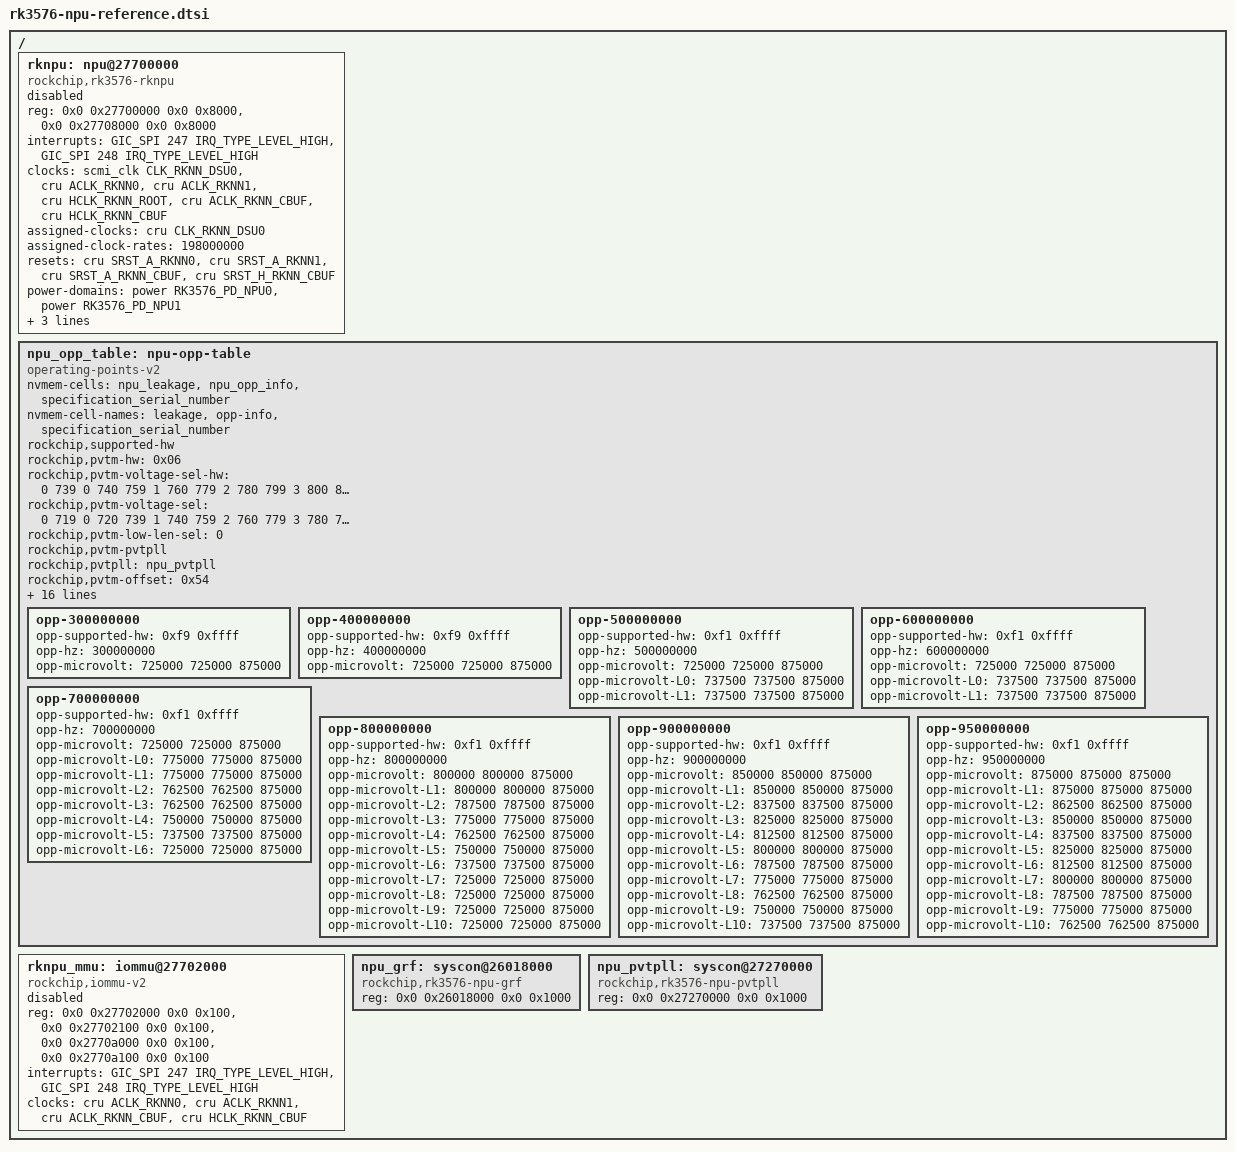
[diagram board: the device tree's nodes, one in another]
// SPDX-License-Identifier: (GPL-2.0+ OR MIT)
/*
 * Copyright (c) 2024 Rockchip Electronics Co., Ltd.
 * 
 * NPU Node Reference - RK3576
 * 
 * Usage:
 *   #include "rk3576-npu-reference.dtsi"
 *   
 * Board-specific configuration (optional):
 *   - Enable desired NPU power domains
 *   - Adjust OPP frequencies
 *   - Configure GPIO reset pins
 *   - Add board-specific iommu mappings
 */

/ {
    // NPU控制器 - 核心节点
    rknpu: npu@27700000 {
        compatible = "rockchip,rk3576-rknpu";
        reg = <0x0 0x27700000 0x0 0x8000>,
              <0x0 0x27708000 0x0 0x8000>;
        interrupts = <GIC_SPI 247 IRQ_TYPE_LEVEL_HIGH>,
                     <GIC_SPI 248 IRQ_TYPE_LEVEL_HIGH>;
        interrupt-names = "npu0_irq", "npu1_irq";
        
        // 时钟配置
        clocks = <&scmi_clk CLK_RKNN_DSU0>, <&cru ACLK_RKNN0>, <&cru ACLK_RKNN1>, 
                 <&cru HCLK_RKNN_ROOT>, <&cru ACLK_RKNN_CBUF>, <&cru HCLK_RKNN_CBUF>;
        clock-names = "clk_npu", "aclk0", "aclk1", "hclk_root",
                      "aclk_cbuf", "hclk_cbuf";
        
        // 时钟分频设置
        assigned-clocks = <&cru CLK_RKNN_DSU0>;
        assigned-clock-rates = <198000000>;
        
        // 复位控制
        resets = <&cru SRST_A_RKNN0>, <&cru SRST_A_RKNN1>,
                 <&cru SRST_A_RKNN_CBUF>, <&cru SRST_H_RKNN_CBUF>;
        reset-names = "srst_a0", "srst_a1",
                      "srst_a_cbuf", "srst_h_cbuf";
        
        // 电源域
        power-domains = <&power RK3576_PD_NPU0>, <&power RK3576_PD_NPU1>;
        power-domain-names = "npu0", "npu1";
        
        // 性能表 - 从npu_opp_table引用
        operating-points-v2 = <&npu_opp_table>;
        
        // IOMMU - 用于DMA地址转换
        iommus = <&rknpu_mmu>;
        
        // 热管理
        #cooling-cells = <2>;
        dynamic-power-coefficient = <2570>;
        
        // 默认禁用，板级dts覆盖为"okay"
        status = "disabled";
    };

    // NPU电源管理表 - 包含电压/频率调优
    npu_opp_table: npu-opp-table {
        compatible = "operating-points-v2";
        
        // OTC OTP数据引用
        nvmem-cells = <&npu_leakage>, <&npu_opp_info>, <&specification_serial_number>;
        nvmem-cell-names = "leakage", "opp-info", "specification_serial_number";
        
        // 硬件版本支持
        rockchip,supported-hw;
        
        // PVTM (Process, Voltage, Temperature Monitoring) 配置
        rockchip,pvtm-hw = <0x06>;
        rockchip,pvtm-voltage-sel-hw = <
            0   739   0
            740 759   1
            760 779   2
            780 799   3
            800 819   4
            820 839   5
            840 859   6
            860 879   7
            880 899   8
            900 9999  9
        >;
        rockchip,pvtm-voltage-sel = <
            0   719   0
            720 739   1
            740 759   2
            760 779   3
            780 799   4
            800 819   5
            820 839   6
            840 859   7
            860 879   8
            880 899   9
            900 9999  10
        >;
        rockchip,pvtm-low-len-sel = <0>;
        rockchip,pvtm-pvtpll;
        rockchip,pvtpll = <&npu_pvtpll>;
        rockchip,pvtm-offset = <0x54>;
        rockchip,pvtm-sample-time = <1100>;
        rockchip,pvtm-freq = <800000>;
        rockchip,pvtm-volt = <750000>;
        rockchip,pvtm-ref-temp = <35>;
        rockchip,pvtm-temp-prop = <0 0>;
        rockchip,pvtm-thermal-zone = "npu-thermal";
        
        // GRF寄存器访问
        rockchip,grf = <&npu_grf>;
        
        // 内存读取 Margin 调优
        volt-mem-read-margin = <
            855000  1
            765000  2
            675000  3
            495000  4
        >;
        
        // 频率交叉点
        intermediate-threshold-freq = <300000>;
        
        // OPP依赖的时钟
        rockchip,opp-clocks = <&cru ACLK_RKNN_CBUF>,
                              <&cru HCLK_RKNN_CBUF>,
                              <&cru PCLK_NPUTOP_ROOT>;
        
        // 温度迟滞和低频电压
        rockchip,temp-hysteresis = <5000>;
        rockchip,low-temp = <15000>;
        rockchip,low-temp-min-volt = <750000>;
        rockchip,init-freq = <950000>;
        
        // 典型 OPP 表 ( RK3576标准版 )
        opp-300000000 {
            opp-supported-hw = <0xf9 0xffff>;
            opp-hz = /bits/ 64 <300000000>;
            opp-microvolt = <725000 725000 875000>;
        };
        opp-400000000 {
            opp-supported-hw = <0xf9 0xffff>;
            opp-hz = /bits/ 64 <400000000>;
            opp-microvolt = <725000 725000 875000>;
        };
        opp-500000000 {
            opp-supported-hw = <0xf1 0xffff>;
            opp-hz = /bits/ 64 <500000000>;
            opp-microvolt = <725000 725000 875000>;
            opp-microvolt-L0 = <737500 737500 875000>;
            opp-microvolt-L1 = <737500 737500 875000>;
        };
        opp-600000000 {
            opp-supported-hw = <0xf1 0xffff>;
            opp-hz = /bits/ 64 <600000000>;
            opp-microvolt = <725000 725000 875000>;
            opp-microvolt-L0 = <737500 737500 875000>;
            opp-microvolt-L1 = <737500 737500 875000>;
        };
        opp-700000000 {
            opp-supported-hw = <0xf1 0xffff>;
            opp-hz = /bits/ 64 <700000000>;
            opp-microvolt = <725000 725000 875000>;
            opp-microvolt-L0 = <775000 775000 875000>;
            opp-microvolt-L1 = <775000 775000 875000>;
            opp-microvolt-L2 = <762500 762500 875000>;
            opp-microvolt-L3 = <762500 762500 875000>;
            opp-microvolt-L4 = <750000 750000 875000>;
            opp-microvolt-L5 = <737500 737500 875000>;
            opp-microvolt-L6 = <725000 725000 875000>;
        };
        opp-800000000 {
            opp-supported-hw = <0xf1 0xffff>;
            opp-hz = /bits/ 64 <800000000>;
            opp-microvolt = <800000 800000 875000>;
            opp-microvolt-L1 = <800000 800000 875000>;
            opp-microvolt-L2 = <787500 787500 875000>;
            opp-microvolt-L3 = <775000 775000 875000>;
            opp-microvolt-L4 = <762500 762500 875000>;
            opp-microvolt-L5 = <750000 750000 875000>;
            opp-microvolt-L6 = <737500 737500 875000>;
            opp-microvolt-L7 = <725000 725000 875000>;
            opp-microvolt-L8 = <725000 725000 875000>;
            opp-microvolt-L9 = <725000 725000 875000>;
            opp-microvolt-L10 = <725000 725000 875000>;
        };
        opp-900000000 {
            opp-supported-hw = <0xf1 0xffff>;
            opp-hz = /bits/ 64 <900000000>;
            opp-microvolt = <850000 850000 875000>;
            opp-microvolt-L1 = <850000 850000 875000>;
            opp-microvolt-L2 = <837500 837500 875000>;
            opp-microvolt-L3 = <825000 825000 875000>;
            opp-microvolt-L4 = <812500 812500 875000>;
            opp-microvolt-L5 = <800000 800000 875000>;
            opp-microvolt-L6 = <787500 787500 875000>;
            opp-microvolt-L7 = <775000 775000 875000>;
            opp-microvolt-L8 = <762500 762500 875000>;
            opp-microvolt-L9 = <750000 750000 875000>;
            opp-microvolt-L10 = <737500 737500 875000>;
        };
        opp-950000000 {
            opp-supported-hw = <0xf1 0xffff>;
            opp-hz = /bits/ 64 <950000000>;
            opp-microvolt = <875000 875000 875000>;
            opp-microvolt-L1 = <875000 875000 875000>;
            opp-microvolt-L2 = <862500 862500 875000>;
            opp-microvolt-L3 = <850000 850000 875000>;
            opp-microvolt-L4 = <837500 837500 875000>;
            opp-microvolt-L5 = <825000 825000 875000>;
            opp-microvolt-L6 = <812500 812500 875000>;
            opp-microvolt-L7 = <800000 800000 875000>;
            opp-microvolt-L8 = <787500 787500 875000>;
            opp-microvolt-L9 = <775000 775000 875000>;
            opp-microvolt-L10 = <762500 762500 875000>;
        };
    };

    // NPU IOMMU - 用于DMA地址映射
    rknpu_mmu: iommu@27702000 {
        compatible = "rockchip,iommu-v2";
        reg = <0x0 0x27702000 0x0 0x100>,
              <0x0 0x27702100 0x0 0x100>,
              <0x0 0x2770a000 0x0 0x100>,
              <0x0 0x2770a100 0x0 0x100>;
        interrupts = <GIC_SPI 247 IRQ_TYPE_LEVEL_HIGH>,
                     <GIC_SPI 248 IRQ_TYPE_LEVEL_HIGH>;
        interrupt-names = "npu0_mmu", "npu1_mmu";
        clocks = <&cru ACLK_RKNN0>, <&cru ACLK_RKNN1>, 
                 <&cru ACLK_RKNN_CBUF>, <&cru HCLK_RKNN_CBUF>;
        clock-names = "aclk0", "aclk1", "a_iface", "h_iface";
        #iommu-cells = <0>;
        status = "disabled";
    };

    // NPU电源管理控制器 (syscon)
    npu_grf: syscon@26018000 {
        compatible = "rockchip,rk3576-npu-grf", "syscon";
        reg = <0x0 0x26018000 0x0 0x1000>;
    };

    // NPU PMU SRAM (PVTPLL)
    npu_pvtpll: syscon@27270000 {
        compatible = "rockchip,rk3576-npu-pvtpll", "syscon";
        reg = <0x0 0x27270000 0x0 0x1000>;
    };
};
